# max32657 register map
Vendor: Maxim-Integrated; Series: ARMCM33; File version: 1.1
CPU: CM4 r2p1, little endian, MPU, FPU, 3 interrupt priority bits
Registers are 32-bit, read-write, reset 0x0 unless marked. A register's access mark holds for its fields unless they carry their own. Offsets are from the block's base; [hi:lo] are bit positions; {n}, {i} and the like mark numbered series.

## NSPC — Non-Secure Privilege Controller.
Base 0x40090000
0x160 APBPRIV — APB Tartet Privileged/Non-privileged PPC Access Register.
  [31:0] PERIPH — Each bit configures the APB PPC to enforce the security access allowed for an individual peripheral.
    1=GCR (Privilege setting for GCR.); 2=SIR (Privilege setting for SIR.); 4=FCR (Privilege setting for FCR.); 8=WDT (Privilege setting for WDT.); 16=AES (Privilege setting for AES.); 32=AESKEYS (Privilege setting for AESKEYS.); 64=CRC (Privilege setting for CRC.); 128=GPIO0 (Privilege setting for GPIO0.); 0x100=TMR0 (Privilege setting for TMR0.); 0x200=TMR1 (Privilege setting for TMR1.); 0x400=TMR2 (Privilege setting for TMR2.); 0x800=TMR3 (Privilege setting for TMR3.); 0x1000=TMR4 (Privilege setting for TMR4.); 0x2000=TMR5 (Privilege setting for TMR5.); 0x4000=I3C (Privilege setting for I3C.); 0x8000=UART (Privilege setting for UART.); 0x10000=SPI (Privilege setting for SPI.); 0x20000=TRNG (Privilege setting for TRNG.); 0x40000=BTLE_DBB (Privilege setting for BTLE DBB.); 0x80000=BTLE_RFFE (Privilege setting for BTLE RFFE.); 0x100000=RSTZ (Privilege setting for RSTZ.); 0x200000=BOOST (Privilege setting for Boost Controller.); 0x400000=TRIMSIR (Privilege setting for TRIMSIR.); 0x1000000=RTC (Privilege setting for RTC.); 0x2000000=WUT0 (Privilege setting for WUT0.); 0x4000000=WUT1 (Privilege setting for WUT1.); 0x8000000=PWRSEQ (Privilege setting for Power Sequencer.); 0x10000000=MCR (Privilege setting for MCR.); 0x1F7FFFFF=ALL (Privilege setting for all peripherals.)
0x170 AHBMPRIV — AHB Privileged/Non-Privileged Non-Secure DMA Access Register.
  [1] DMA — Control access for transactions coming from the Non-Secure DMA.

## RSTZ — RSTZ Controller
Base 0x50004800
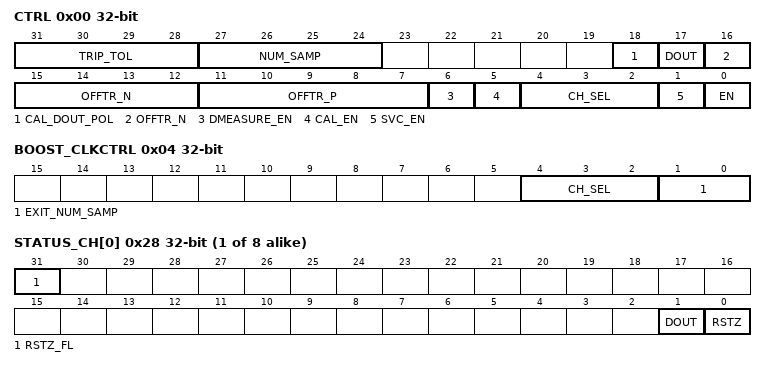
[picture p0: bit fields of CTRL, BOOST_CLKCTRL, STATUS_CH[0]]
0x00 CTRL — RSTZ Control Register.
  [31:28] TRIP_TOL — Number of failed DOUT captures (tolerance) before corresponding RSTZ signal is tripped.
  [27:24] NUM_SAMP — Number of captures per sample.
  [18] CAL_DOUT_POL — Calibration DOUT Polarity.
  [17] DOUT — Comparator Result.
  [16:12] OFFTR_N — Offset Trim for negative comparator.
  [11:7] OFFTR_P — Offset Trim for positive comparator.
  [6] DMEASURE_EN — Direct Measure mode enable.
  [5] CAL_EN — Calibration mode enable.
  [4:2] CH_SEL — Channel Select.
  [1] SVC_EN — Enable the SVC.
  [0] EN — Enable channels.
0x04 BOOST_CLKCTRL — Boost Clock Control Register.
  [4:2] CH_SEL — Select when channel the output of the boost converter is monitored on.
  [1:0] EXIT_NUM_SAMP — Defines how many samples needed of boost output channel to perform when exiting low-power mode before returning to normal active operation.
{0x28+4i} STATUS_CH[{i}] (i=0..7) — Channel X Status Register.
  [31] RSTZ_FL — RSTZ Flag indicates the RSTZ was tripped at some point since the last time being cleared.
  [1] DOUT ro — Store the most recent DOUT capture for a given channel.
  [0] RSTZ ro — Result of most recent sample result.

## RTC — Real Time Clock and Alarm.
Base 0x50006000
0x00 SEC reset not defined — RTC Second Counter. This register contains the 32-bit second counter.
  [31:0] SEC — Seconds Counter.
0x04 SSEC reset not defined — RTC Sub-second Counter. This counter increments at 256Hz. RTC_SEC is incremented when this register rolls over from 0xFF to 0x00.
  [11:0] SSEC — Sub-Seconds Counter (12-bit).
0x08 TODA reset not defined — Time-of-day Alarm.
  [19:0] TOD_ALARM
0x0C SSECA reset not defined — RTC sub-second alarm. This register contains the reload value for the sub-second alarm.
  [31:0] SSEC_ALARM — This register contains the reload value for the sub-second alarm.
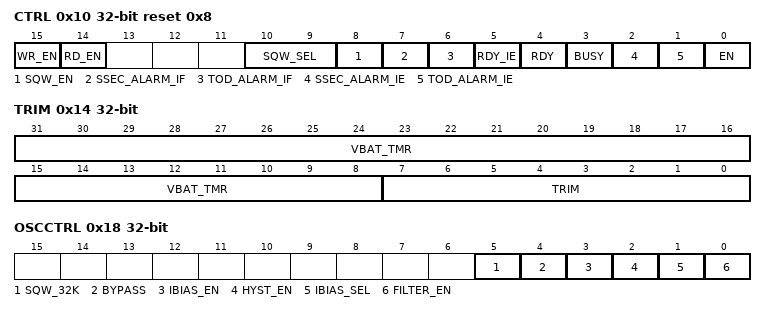
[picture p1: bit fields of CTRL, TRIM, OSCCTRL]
0x10 CTRL reset 0x8 (reset mask 0xFFFFFF38) — RTC Control Register.
  [15] WR_EN — Write Enable. This register bit serves as a protection mechanism against unintentional writes to critical RTC bits.
    0=Ignored; 1=Allowed
  [14] RD_EN — Asynchronous Counter Read Enable.
    0=Synchronous; 1=Asynchronous
  [10:9] SQW_SEL — Frequency Output Selection. When SQE=1, these bits specify the output frequency on the SQW pin.
    0=freq1Hz (1 Hz (Compensated).); 1=freq512Hz (512 Hz (Compensated).); 2=freq4KHz (4 KHz.)
  [8] SQW_EN — Square Wave Output Enable.
    0=dis (Disable.); 1=en (Enable.)
  [7] SSEC_ALARM_IF ro — Sub-second Alarm Interrupt Flag. This alarm is qualified as wake-up source to the processor.
    0=inactive (Not active.); 1=pending (Active.)
  [6] TOD_ALARM_IF ro — Time-of-Day Alarm Interrupt Flag. This alarm is qualified as wake-up source to the processor.
    0=inactive (Not active.); 1=pending (Active.)
  [5] RDY_IE — RTC Ready Interrupt Enable.
    0=dis (Disable.); 1=en (Enable.)
  [4] RDY — RTC Ready. This bit is set to 1 by hardware when the RTC count registers update. It can be cleared to 0 by software at any time. It will also be cleared to 0 by hardware just prior to an update of the RTC count register.
    0=busy (Register has not updated.); 1=ready
  [3] BUSY ro — RTC Busy. This bit is set to 1 by hardware when changes to RTC registers required a synchronized version of the register to be in place. This bit is automatically cleared by hardware.
    0=idle; 1=busy
  [2] SSEC_ALARM_IE — Alarm Sub-second Interrupt Enable. Change to this bit is effective only after BUSY is cleared from 1 to 0.
    0=dis (Disable.); 1=en (Enable.)
  [1] TOD_ALARM_IE — Alarm Time-of-Day Interrupt Enable. Change to this bit is effective only after BUSY is cleared from 1 to 0.
    0=dis (Disable.); 1=en (Enable.)
  [0] EN — Real Time Clock Enable. This bit enables the Real Time Clock. This bit can only be written when WE=1 and BUSY =0. Change to this bit is effective only after BUSY is cleared from 1 to 0.
    0=dis (Disable.); 1=en (Enable.)
0x14 TRIM reset not defined — RTC Trim Register.
  [31:8] VBAT_TMR — VBAT Timer Value. When RTC is running off of VBAT, this field is incremented every 32 seconds.
  [7:0] TRIM — RTC Trim. This register contains the 2's complement value that specifies the trim resolution. Each increment or decrement of the bit adds or subtracts 1ppm at each 4KHz clock value, with a maximum correction of +/- 127ppm.
0x18 OSCCTRL reset not defined — RTC Oscillator Control Register.
  [5] SQW_32K — RTC 32kHz Square Wave Output
    0=dis (Disable.); 1=en (Enable.)
  [4] BYPASS — RTC Crystal Bypass
    0=dis (Disable.); 1=en (Enable.)
  [3] IBIAS_EN — RTC IBIAS Enable.
  [2] HYST_EN — RTC Hysteresis Enable.
  [1] IBIAS_SEL — IBIAS Select.
    0=2x; 1=4x
  [0] FILTER_EN — Enable Filter.
